# MSPM0L134X register map
Vendor: Texas Instruments; File version: This preliminary header file does not have a version number - build date: 2023-02-21 16:43:37
CPU: CM0 r0p1, little endian, MPU, no FPU, 3 interrupt priority bits
Registers are 32-bit, read-write, reset 0x0 unless marked. A register's access mark holds for its fields unless they carry their own. Offsets are from the block's base; [hi:lo] are bit positions.

## DEBUGSS — DSSM
Base 0x400C7000
0x1020 IIDX ro — Interrupt index
  [7:0] IIDX_STAT — Interrupt index status
    0=IIDX_STAT_NO_INTR (NO_INTR); 1=IIDX_STAT_TXIFG (TXIFG); 2=IIDX_STAT_RXIFG (RXIFG); 3=IIDX_STAT_PWRUP (PWRUP); 4=IIDX_STAT_PWRDWN (PWRDWN)
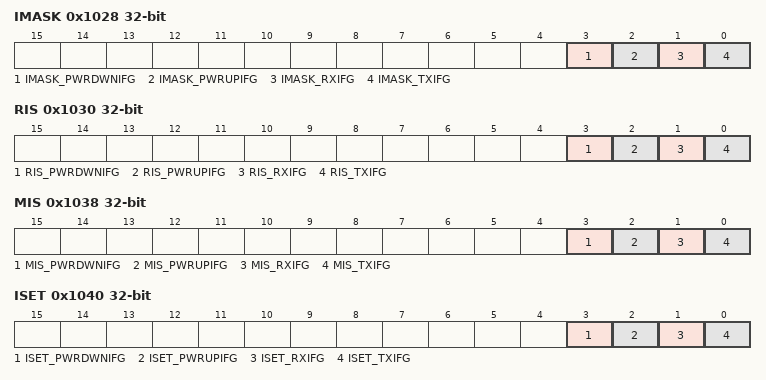
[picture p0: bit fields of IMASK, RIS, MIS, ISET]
0x1028 IMASK — Interrupt mask
  [3] IMASK_PWRDWNIFG — Masks PWRDWNIFG in MIS register
    0=IMASK_PWRDWNIFG_CLR (CLR); 1=IMASK_PWRDWNIFG_SET (SET)
  [2] IMASK_PWRUPIFG — Masks PWRUPIFG in MIS register
    0=IMASK_PWRUPIFG_CLR (CLR); 1=IMASK_PWRUPIFG_SET (SET)
  [1] IMASK_RXIFG — Masks RXIFG in MIS register
    0=IMASK_RXIFG_CLR (CLR); 1=IMASK_RXIFG_SET (SET)
  [0] IMASK_TXIFG — Masks TXIFG in MIS register
    0=IMASK_TXIFG_CLR (CLR); 1=IMASK_TXIFG_SET (SET)
0x1030 RIS ro — Raw interrupt status
  [3] RIS_PWRDWNIFG — Raw interrupt status for PWRDWNIFG
    0=RIS_PWRDWNIFG_CLR (CLR); 1=RIS_PWRDWNIFG_SET (SET)
  [2] RIS_PWRUPIFG — Raw interrupt status for PWRUPIFG
    0=RIS_PWRUPIFG_CLR (CLR); 1=RIS_PWRUPIFG_SET (SET)
  [1] RIS_RXIFG — Raw interrupt status for RXIFG
    0=RIS_RXIFG_CLR (CLR); 1=RIS_RXIFG_SET (SET)
  [0] RIS_TXIFG — Raw interrupt status for TXIFG
    0=RIS_TXIFG_CLR (CLR); 1=RIS_TXIFG_SET (SET)
0x1038 MIS ro — Masked interrupt status
  [3] MIS_PWRDWNIFG — Masked interrupt status for PWRDWNIFG
    0=MIS_PWRDWNIFG_CLR (CLR); 1=MIS_PWRDWNIFG_SET (SET)
  [2] MIS_PWRUPIFG — Masked interrupt status for PWRUPIFG
    0=MIS_PWRUPIFG_CLR (CLR); 1=MIS_PWRUPIFG_SET (SET)
  [1] MIS_RXIFG — Masked interrupt status for RXIFG
    0=MIS_RXIFG_CLR (CLR); 1=MIS_RXIFG_SET (SET)
  [0] MIS_TXIFG — Masked interrupt status for TXIFG
    0=MIS_TXIFG_CLR (CLR); 1=MIS_TXIFG_SET (SET)
0x1040 ISET wo — Interrupt set
  [3] ISET_PWRDWNIFG — Sets PWRDWNIFG in RIS register
    0=ISET_PWRDWNIFG_NO_EFFECT (NO_EFFECT); 1=ISET_PWRDWNIFG_SET (SET)
  [2] ISET_PWRUPIFG — Sets PWRUPIFG in RIS register
    0=ISET_PWRUPIFG_NO_EFFECT (NO_EFFECT); 1=ISET_PWRUPIFG_SET (SET)
  [1] ISET_RXIFG — Sets RXIFG in RIS register
    0=ISET_RXIFG_NO_EFFECT (NO_EFFECT); 1=ISET_RXIFG_SET (SET)
  [0] ISET_TXIFG — Sets TXIFG in RIS register
    0=ISET_TXIFG_NO_EFFECT (NO_EFFECT); 1=ISET_TXIFG_SET (SET)
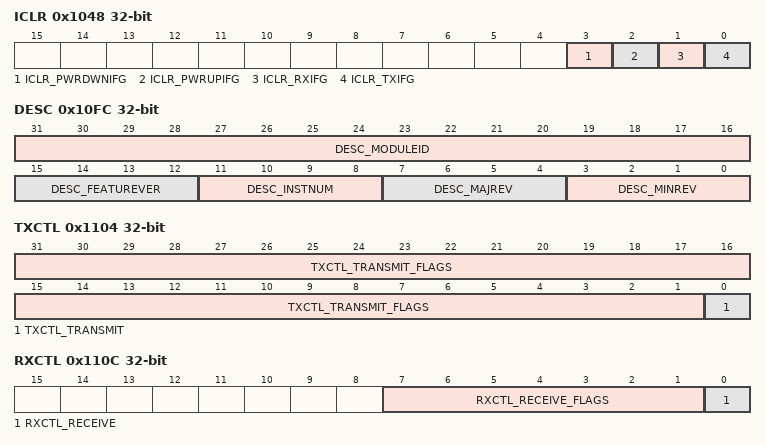
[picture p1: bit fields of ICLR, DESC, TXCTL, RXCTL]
0x1048 ICLR wo — Interrupt clear
  [3] ICLR_PWRDWNIFG — Clears PWRDWNIFG in RIS register
    0=ICLR_PWRDWNIFG_NO_EFFECT (NO_EFFECT); 1=ICLR_PWRDWNIFG_CLR (CLR)
  [2] ICLR_PWRUPIFG — Clears PWRUPIFG in RIS register
    0=ICLR_PWRUPIFG_NO_EFFECT (NO_EFFECT); 1=ICLR_PWRUPIFG_CLR (CLR)
  [1] ICLR_RXIFG — Clears RXIFG in RIS register
    0=ICLR_RXIFG_NO_EFFECT (NO_EFFECT); 1=ICLR_RXIFG_CLR (CLR)
  [0] ICLR_TXIFG — Clears TXIFG in RIS register
    0=ICLR_TXIFG_NO_EFFECT (NO_EFFECT); 1=ICLR_TXIFG_CLR (CLR)
0x10E0 EVT_MODE ro — Event Mode
  [1:0] EVT_MODE_INT0_CFG — Event line mode select for peripheral events
    0=EVT_MODE_INT0_CFG_DISABLE (DISABLE); 1=EVT_MODE_INT0_CFG_SOFTWARE (SOFTWARE); 2=EVT_MODE_INT0_CFG_HARDWARE (HARDWARE)
0x10FC DESC ro — Module Description
  [31:16] DESC_MODULEID — Module identification contains a unique peripheral identification number. The assignments are maintained in a central database for all of the platform modules to ensure uniqueness.
  [15:12] DESC_FEATUREVER — Feature Set for the module *instance*
  [11:8] DESC_INSTNUM — Instance Number within the device. This will be a parameter to the RTL for modules that can have multiple instances
  [7:4] DESC_MAJREV — Major rev of the IP
  [3:0] DESC_MINREV — Minor rev of the IP
0x1100 TXD ro — Transmit data register
  [31:0] TXD_TX_DATA — Contains data written by an external debug tool to the SEC-AP TXDATA register
0x1104 TXCTL ro — Transmit control register
  [31:1] TXCTL_TRANSMIT_FLAGS — Generic TX flags that can be set by external debug tool. Functionality is defined by SW.
  [0] TXCTL_TRANSMIT — Indicates data request in DSSM.TXD, set on write via Debug AP to DSSM.TXD. A read of the DSSM.TXD register by SW will clear the TX field. The tool can check that TXD is empty by reading this field.
    0=TXCTL_TRANSMIT_EMPTY (EMPTY); 1=TXCTL_TRANSMIT_FULL (FULL)
0x1108 RXD — Receive data register
  [31:0] RXD_RX_DATA — Contains data written by SM/OW.
0x110C RXCTL — Receive control register
  [7:1] RXCTL_RECEIVE_FLAGS — Generic RX flags that can be set by SW and read by external debug tool. Functionality is defined by SW.
  [0] RXCTL_RECEIVE ro — Indicates SW write to the DSSM.RXD register. A read of the DSSM.RXD register by SWD Access Port will clear the RX field.
    0=RXCTL_RECEIVE_EMPTY (EMPTY); 1=RXCTL_RECEIVE_FULL (FULL)
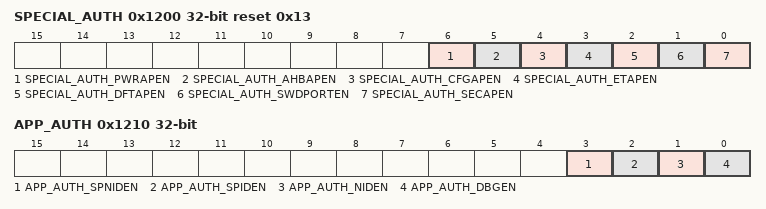
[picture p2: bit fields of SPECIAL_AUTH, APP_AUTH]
0x1200 SPECIAL_AUTH ro reset 0x13 — Special enable authorization register
  [6] SPECIAL_AUTH_PWRAPEN — An active high input. When asserted (and SWD access is also permitted), the debug tools can then access the PWR-AP to power and reset state of the CPU. When deasserted, a DAPBUS firewall will isolate the AP and prevent access.
    0=SPECIAL_AUTH_PWRAPEN_DISABLE (DISABLE); 1=SPECIAL_AUTH_PWRAPEN_ENABLE (ENABLE)
  [5] SPECIAL_AUTH_AHBAPEN — Disabling / enabling debug access to the M0+ Core via the AHB-AP DAP bus isolation.
    0=SPECIAL_AUTH_AHBAPEN_DISABLE (DISABLE); 1=SPECIAL_AUTH_AHBAPEN_ENABLE (ENABLE)
  [4] SPECIAL_AUTH_CFGAPEN — An active high input. When asserted (and SWD access is also permitted), the debug tools can use the Config-AP to read device configuration information. When deasserted, a DAPBUS firewall will isolate the AP and prevent access to the Config-AP.
    0=SPECIAL_AUTH_CFGAPEN_DISABLE (DISABLE); 1=SPECIAL_AUTH_CFGAPEN_ENABLE (ENABLE)
  [3] SPECIAL_AUTH_ETAPEN — An active high input. When asserted (and SWD access is also permitted), the debug tools can then access an ET-AP external to the DebugSS lite. When deasserted, a DAPBUS firewall will isolate the AP and prevent access.
    0=SPECIAL_AUTH_ETAPEN_DISABLE (DISABLE); 1=SPECIAL_AUTH_ETAPEN_ENABLE (ENABLE)
  [2] SPECIAL_AUTH_DFTAPEN — An active high input. When asserted (and SWD access is also permitted), the debug tools can then access the DFT-AP external to the DebugSS lite. When deasserted, a DAPBUS firewall will isolate the AP and prevent access.
    0=SPECIAL_AUTH_DFTAPEN_DISABLE (DISABLE); 1=SPECIAL_AUTH_DFTAPEN_ENABLE (ENABLE)
  [1] SPECIAL_AUTH_SWDPORTEN — When asserted, the SW-DP functions normally. When deasserted, the SW-DP effectively disables all external debug access.
    0=SPECIAL_AUTH_SWDPORTEN_DISABLE (DISABLE); 1=SPECIAL_AUTH_SWDPORTEN_ENABLE (ENABLE)
  [0] SPECIAL_AUTH_SECAPEN — An active high input. When asserted (and SWD access is also permitted), the debug tools can use the Security-AP to communicate with security control logic. When deasserted, a DAPBUS firewall will isolate the AP and prevent access to the Security-AP.
    0=SPECIAL_AUTH_SECAPEN_DISABLE (DISABLE); 1=SPECIAL_AUTH_SECAPEN_ENABLE (ENABLE)
0x1210 APP_AUTH ro — Application CPU0 authorization register
  [3] APP_AUTH_SPNIDEN — Secure non-invasive debug enable.
    0=APP_AUTH_SPNIDEN_DISABLE (DISABLE); 1=APP_AUTH_SPNIDEN_ENABLE (ENABLE)
  [2] APP_AUTH_SPIDEN — Secure invasive debug enable.
    0=APP_AUTH_SPIDEN_DISABLE (DISABLE); 1=APP_AUTH_SPIDEN_ENABLE (ENABLE)
  [1] APP_AUTH_NIDEN — Controls non-invasive debug enable.
    0=APP_AUTH_NIDEN_DISABLE (DISABLE); 1=APP_AUTH_NIDEN_ENABLE (ENABLE)
  [0] APP_AUTH_DBGEN — Controls invasive debug enable.
    0=APP_AUTH_DBGEN_DISABLE (DISABLE); 1=APP_AUTH_DBGEN_ENABLE (ENABLE)
